# M061 register map
File version: 2.0.2.1
CPU: 
Registers are 32-bit, read-write, reset 0x0 unless marked. A register's access mark holds for its fields unless they carry their own. Offsets are from the block's base; [hi:lo] are bit positions; {n}, {i} and the like mark numbered series.

## PE — General Purpose Input_Output Port (PE)
Base 0x400C0400
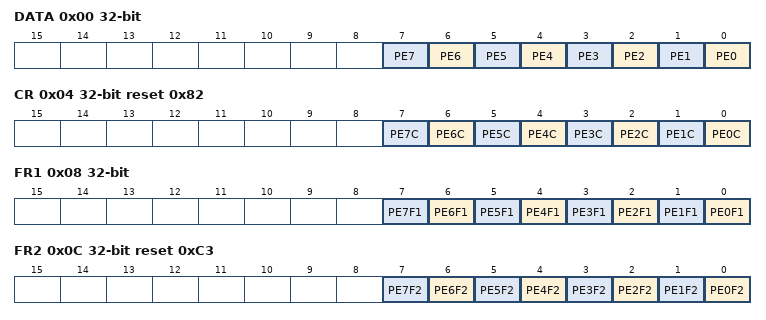
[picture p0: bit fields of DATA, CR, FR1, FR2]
0x00 DATA — PE Data Register
  [n] PE{n} (n=0..7)
0x04 CR reset 0x82 — PE Control Register
  [n] PE{n}C (n=0..7)
0x08 FR1 — PE Function Register 1
  [n] PE{n}F1 (n=0..7)
0x0C FR2 reset 0xC3 — PE Function Register 2
  [n] PE{n}F2 (n=0..7)
0x10 FR3 — PE Function Register 3
  [3] PE3F3
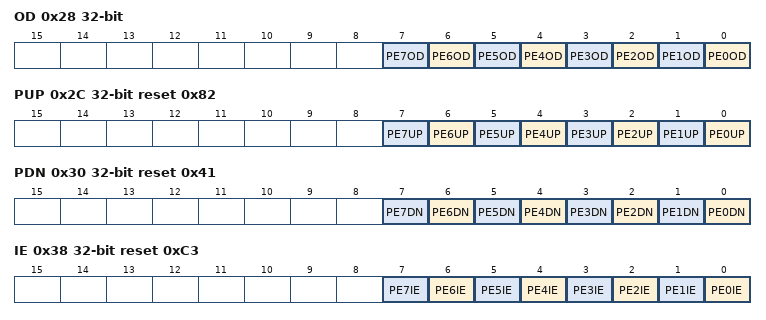
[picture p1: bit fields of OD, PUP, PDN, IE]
0x28 OD — PE Open Drain Control Register
  [n] PE{n}OD (n=0..7)
0x2C PUP reset 0x82 — PE Pull-Up Control Register
  [n] PE{n}UP (n=0..7)
0x30 PDN reset 0x41 — PE Pull-Down Control Register
  [n] PE{n}DN (n=0..7)
0x38 IE reset 0xC3 — PE Input Enable Control Register
  [n] PE{n}IE (n=0..7)

## PF — General Purpose Input_Output Port (PF)
Base 0x400C0500
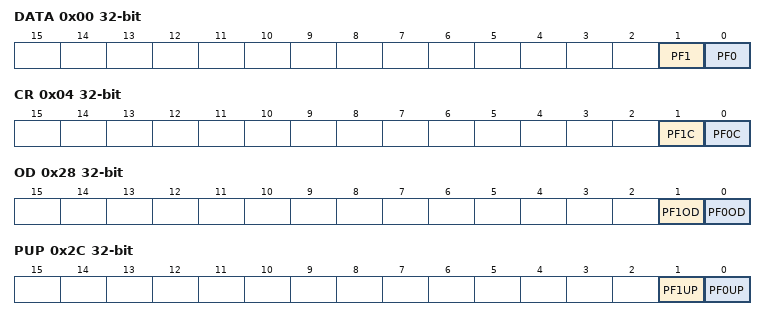
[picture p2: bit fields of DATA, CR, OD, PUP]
0x00 DATA — PF Data Register
  [1] PF1, [0] PF0
0x04 CR — PF Control Register
  [1] PF1C, [0] PF0C
0x08 FR1 — PF Function Register 1
  [1] PF1F1
0x28 OD — PF Open Drain Control Register
  [1] PF1OD, [0] PF0OD
0x2C PUP — PF Pull-Up Control Register
  [1] PF1UP, [0] PF0UP
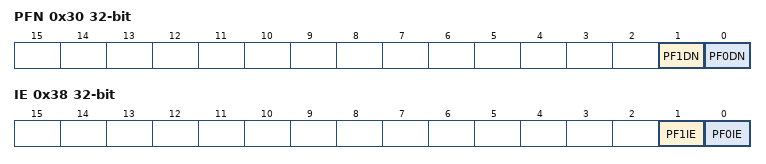
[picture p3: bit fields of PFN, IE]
0x30 PFN — PF Pull-Down Control Register
  [1] PF1DN, [0] PF0DN
0x38 IE — PF Input Enable Control Register
  [1] PF1IE, [0] PF0IE

## PG — General Purpose Input_Output Port (PG)
Base 0x400C0600
0x00 DATA — PG Data Register
  [0] PG0
0x04 CR — PG Control Register
  [0] PG0C
0x08 FR1 — PG Function Register 1
  [0] PG0F1
0x0C FR2 — PG Function Register 2
  [0] PG0F2
0x28 OD — PG Open Drain Control Register
  [0] PG0OD
0x2C PUP — PG Pull-Up Control Register
  [0] PG0UP
0x30 PGN — PG Pull-Down Control Register
  [0] PG0DN
0x38 IE — PG Input Enable Control Register
  [0] PG0IE

## PH — General Purpose Input_Output Port (PH)
Base 0x400C0700
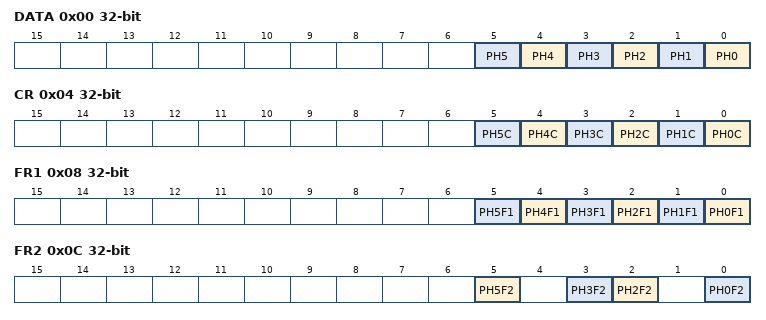
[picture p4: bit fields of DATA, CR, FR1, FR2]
0x00 DATA — PH Data Register
  [n] PH{n} (n=0..5)
0x04 CR — PH Control Register
  [n] PH{n}C (n=0..5)
0x08 FR1 — PH Function Register 1
  [n] PH{n}F1 (n=0..5)
0x0C FR2 — PH Function Register 2
  [5] PH5F2, [3] PH3F2, [2] PH2F2, [0] PH0F2
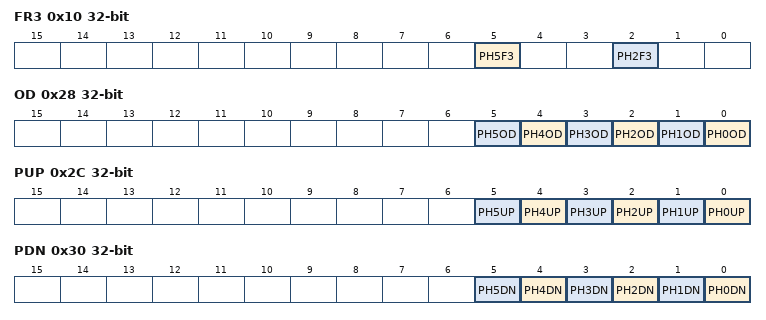
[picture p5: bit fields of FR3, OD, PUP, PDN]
0x10 FR3 — PH Function Register 3
  [5] PH5F3, [2] PH2F3
0x28 OD — PH OPHn Drain Control Register
  [n] PH{n}OD (n=0..5)
0x2C PUP — PH Pull-Up Control Register
  [n] PH{n}UP (n=0..5)
0x30 PDN — PH Pull-Down Control Register
  [n] PH{n}DN (n=0..5)
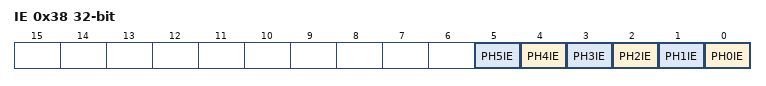
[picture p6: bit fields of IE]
0x38 IE — PH Input Enable Control Register
  [n] PH{n}IE (n=0..5)

## PI — General Purpose Input_Output Port (PI)
Base 0x400C0800
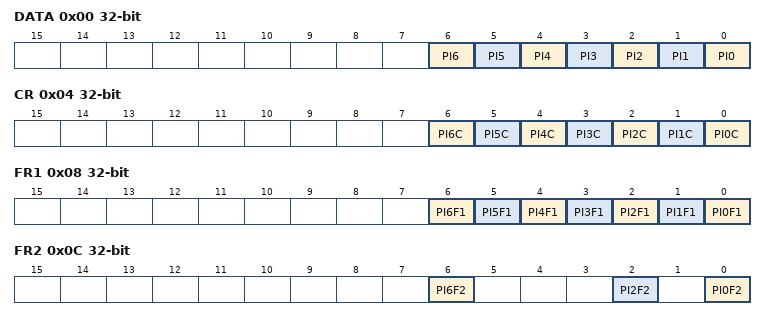
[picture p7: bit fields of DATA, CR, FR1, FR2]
0x00 DATA — PI Data Register
  [n] PI{n} (n=0..6)
0x04 CR — PI Control Register
  [n] PI{n}C (n=0..6)
0x08 FR1 — PI Function Register 1
  [n] PI{n}F1 (n=0..6)
0x0C FR2 — PI Function Register 2
  [6] PI6F2, [2] PI2F2, [0] PI0F2
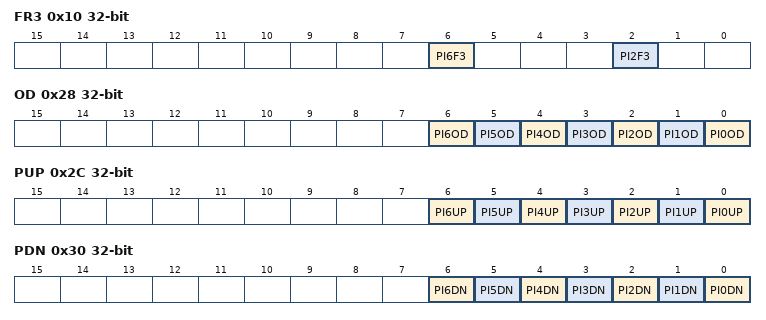
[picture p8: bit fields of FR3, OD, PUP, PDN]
0x10 FR3 — PI Function Register 3
  [6] PI6F3, [2] PI2F3
0x28 OD — PI OPIn Drain Control Register
  [n] PI{n}OD (n=0..6)
0x2C PUP — PI Pull-Up Control Register
  [n] PI{n}UP (n=0..6)
0x30 PDN — PI Pull-Down Control Register
  [n] PI{n}DN (n=0..6)
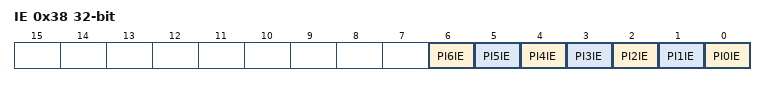
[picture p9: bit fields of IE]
0x38 IE — PI Input Enable Control Register
  [n] PI{n}IE (n=0..6)

## PJ — General Purpose Input_Output Port (PJ)
Base 0x400C0900
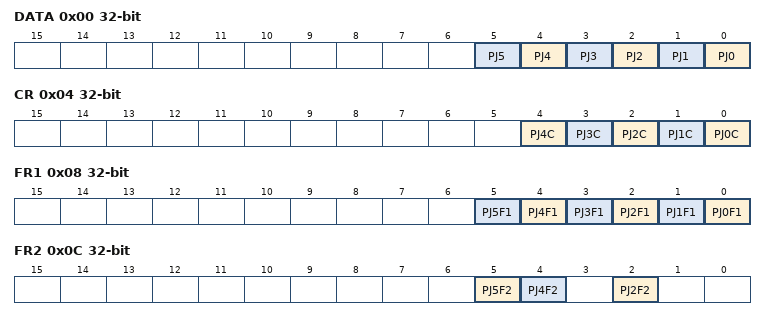
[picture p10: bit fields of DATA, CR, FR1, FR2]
0x00 DATA — PJ Data Register
  [n] PJ{n} (n=0..5)
0x04 CR — PJ Control Register
  [n] PJ{n}C (n=0..4)
0x08 FR1 — PJ Function Register 1
  [n] PJ{n}F1 (n=0..5)
0x0C FR2 — PJ Function Register 2
  [5] PJ5F2, [4] PJ4F2, [2] PJ2F2
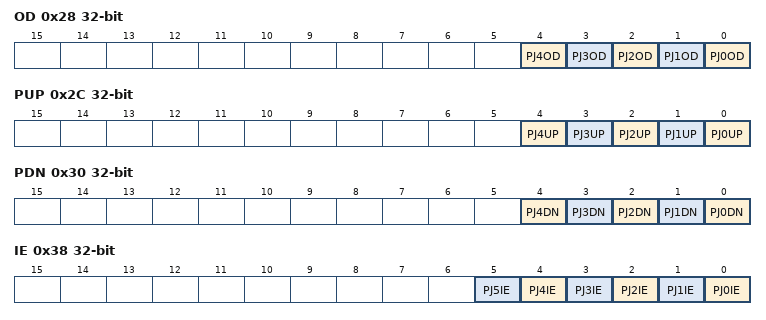
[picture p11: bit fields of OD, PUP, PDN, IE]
0x28 OD — PJ OPJn Drain Control Register
  [n] PJ{n}OD (n=0..4)
0x2C PUP — PJ Pull-Up Control Register
  [n] PJ{n}UP (n=0..4)
0x30 PDN — PJ Pull-Down Control Register
  [n] PJ{n}DN (n=0..4)
0x38 IE — PJ Input Enable Control Register
  [n] PJ{n}IE (n=0..5)

## PK — General Purpose Input_Output Port (PK)
Base 0x400C0A00
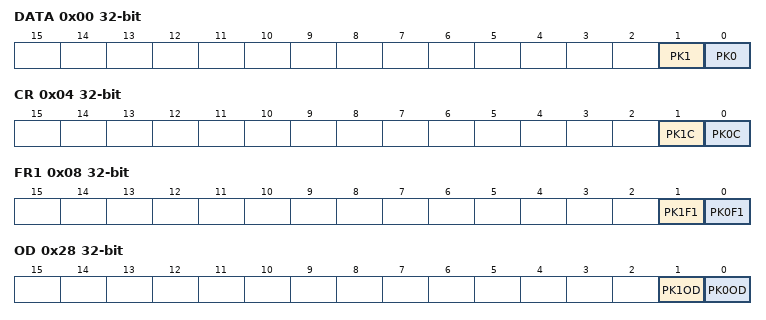
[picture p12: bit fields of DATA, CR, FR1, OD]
0x00 DATA — PK Data Register
  [1] PK1, [0] PK0
0x04 CR — PK Control Register
  [1] PK1C, [0] PK0C
0x08 FR1 — PK Function Register 1
  [1] PK1F1, [0] PK0F1 ro
0x28 OD — PK Open Drain Control Register
  [1] PK1OD, [0] PK0OD
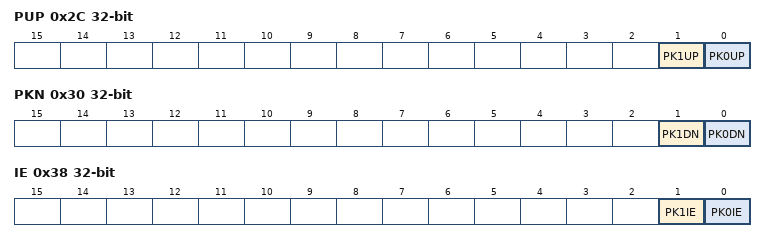
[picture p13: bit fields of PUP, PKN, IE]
0x2C PUP — PK Pull-Up Control Register
  [1] PK1UP, [0] PK0UP
0x30 PKN — PK Pull-Down Control Register
  [1] PK1DN, [0] PK0DN
0x38 IE — PK Input Enable Control Register
  [1] PK1IE, [0] PK0IE
